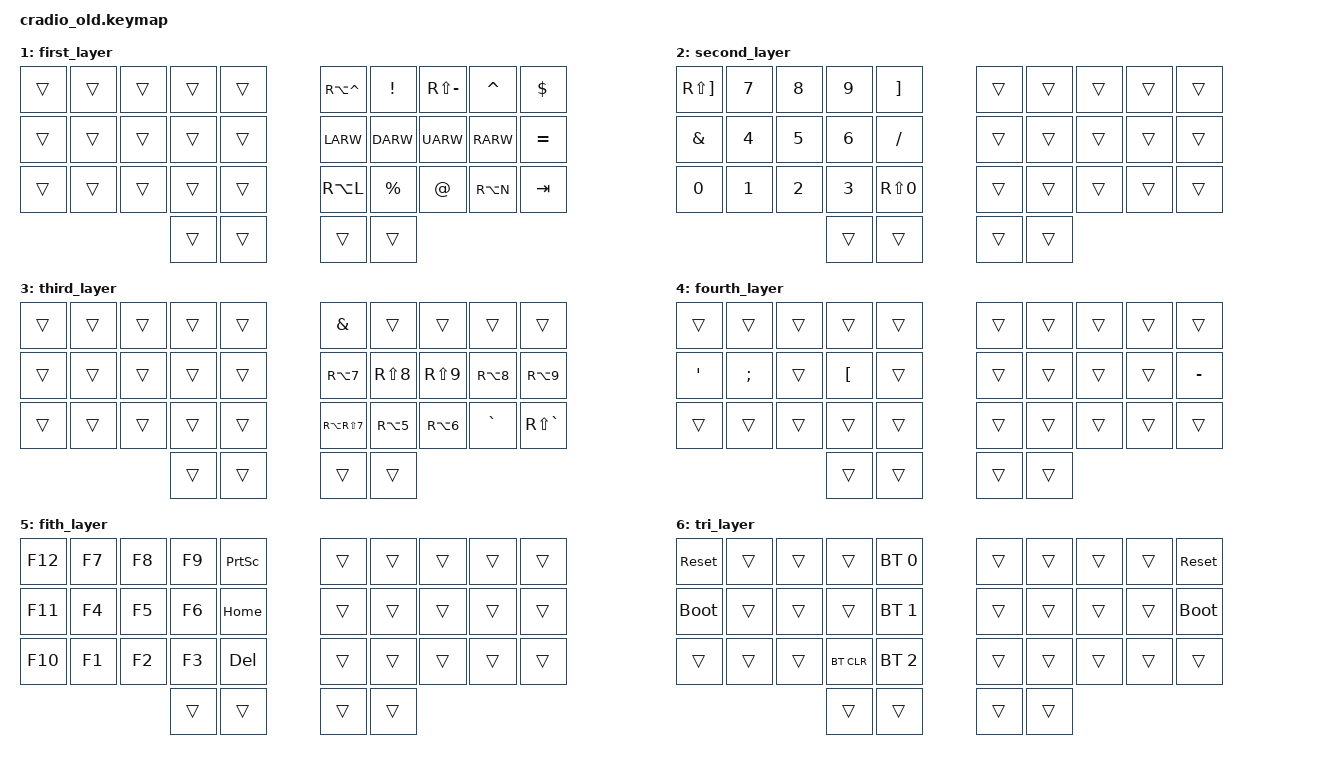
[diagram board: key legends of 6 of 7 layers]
// Copyright (c) 2022 The ZMK Contributors
// SPDX-License-Identifier: MIT

#include <behaviors.dtsi>
#include <dt-bindings/zmk/keys.h>
#include <dt-bindings/zmk/bt.h>

// Home row mods macro
#define HRML(k1,k2,k3,k4) &ht LCTRL k1  &ht LALT k2  &ht LGUI k3  &ht LSHFT k4
#define HRMR(k1,k2,k3,k4) &ht RSHFT k1  &ht RGUI k2  &ht RALT k3  &ht RCTRL k4

#define DEFAULT 0
#define QWERTZ 1
#define NAV 2
#define NUMS 3
#define SIGNS 4
#define DE 5
#define FUNC 6
#define SYSTEM 7


&lt {
    flavor = "tap-preferred";
    tapping-term-ms = <200>;
    quick-tap-ms = <200>;
};

/ {
    behaviors {
        ht: hold_tap {
            compatible = "zmk,behavior-hold-tap";
            #binding-cells = <2>;
            flavor = "tap-preferred";
            tapping-term-ms = <200>;
            quick-tap-ms = <200>;
            require-prior-idle-ms = <100>;
            bindings = <&kp>, <&kp>;
        };
    };

    conditional_layers {
        compatible = "zmk,conditional-layers";
        tri_layer {
            if-layers = <NAV NUMS>;
            then-layer = <SYSTEM>;
        };
    };

    keymap {
        compatible = "zmk,keymap";
        default_layer {
                        bindings = <
        //╭──────────┬──────────┬──────────┬──────────┬──────────╮   ╭──────────┬──────────┬──────────┬──────────┬──────────╮
        //│  Q       │  W       │  E       │  R       │  T       │   │  Y       │  U       │  I       │  O       │ - _      │
            &kp Q      &kp W      &kp E      &kp R      &kp T          &kp Y      &kp U      &kp I      &kp O      &kp FSLH
        //├──────────┼──────────┼──────────┼──────────┼──────────┤   ├──────────┼──────────┼──────────┼──────────┼──────────┤
        //│  A       │  S       │  D       │  F       │  G       │   │  H       │  J       │  K       │  L       │ P        │
            HRML(A,        S,         D,         F)     &kp G          &kp H      HRMR(J,        K,         L,        P)
        //├──────────┼──────────┼──────────┼──────────┼──────────┤   ├──────────┼──────────┼──────────┼──────────┼──────────┤
        //│  Z       │  X       │  C       │  V       │  B       │   │  N       │  M       │ , <      │ . >      │ # '      │
            &kp Z      &kp X      &kp C      &kp V      &kp B          &kp N      &kp M      &kp COMMA  &kp DOT    &lt FUNC BSLH
        //╰──────────┴──────────┴──────────┼──────────┼──────────┤   ├──────────┼──────────┼──────────┴──────────┴──────────╯
                                            &lt SIGNS ESC   &lt NAV BSPC   &lt NUMS SPACE &lt DE ENTER
        //                                 ╰──────────┴──────────╯   ╰──────────┴──────────╯
            >;
        };



        first_layer {
            bindings = <
        //╭──────────┬──────────┬──────────┬──────────┬──────────╮   ╭──────────┬──────────┬──────────┬──────────┬──────────╮
        //│          │          │          │          │          │   │ ^        │ !        │ ?        │ &        │  $       │
            &trans     &trans     &trans     &trans     &trans        &kp RA(CARET) &kp EXCL &kp RS(MINUS) &kp CARET &kp DLLR
        //├──────────┼──────────┼──────────┼──────────┼──────────┤   ├──────────┼──────────┼──────────┼──────────┼──────────┤
        //│          │          │          │          │          │   │ LEFT     │ DOWN     │ UP       │ RIGHT    │  ;       │
            &trans     &trans     &trans     &trans     &trans         &kp LARW   &kp DARW   &kp UARW   &kp RARW   &kp EQUAL
        //├──────────┼──────────┼──────────┼──────────┼──────────┤   ├──────────┼──────────┼──────────┼──────────┼──────────┤
        //│          │          │          │          │          │   │ @        │ %        │ "        │ ~        │          │
            &trans     &trans     &trans     &trans     &trans         &kp RA(L)  &kp PRCNT  &kp AT     &kp RA(N)  &kp TAB
        //╰──────────┴──────────┴──────────┼──────────┼──────────┤   ├──────────┼──────────┼──────────┴──────────┴──────────╯
                                             &trans     &trans            &trans     &trans
        //                                 ╰──────────┴──────────╯   ╰──────────┴──────────╯
            >;
        };

        second_layer {
            bindings = <
        //╭──────────┬──────────┬──────────┬──────────┬──────────╮   ╭──────────┬──────────┬──────────┬──────────┬──────────╮
        //│  *       │  7       │  8       │  9       │  +       │   │          │          │          │          │          │
           &kp RS(RBKT) &kp N7    &kp N8     &kp N9     &kp RBKT      &trans     &trans     &trans     &trans     &trans 
        //├──────────┼──────────┼──────────┼──────────┼──────────┤   ├──────────┼──────────┼──────────┼──────────┼──────────┤
        //│  7       │  4       │  5       │  6       │  -       │   │          │          │          │          │          │
            &kp AMPS   &kp N4     &kp N5     &kp N6     &kp FSLH        &trans     &trans     &trans     &trans     &trans 
        //├──────────┼──────────┼──────────┼──────────┼──────────┤   ├──────────┼──────────┼──────────┼──────────┼──────────┤
        //│  0       │  1       │  2       │  3       │  =       │   │          │          │          │          │          │
            &kp N0     &kp N1     &kp N2     &kp N3     &kp RS(N0)      &trans     &trans     &trans     &trans     &trans
        //╰──────────┴──────────┴──────────┼──────────┼──────────┤   ├──────────┼──────────┼──────────┴──────────┴──────────╯
                                             &trans     &trans         &trans     &trans
        //                                 ╰──────────┴──────────╯   ╰──────────┴──────────╯
            >;
        };

        third_layer {
            bindings = <
        //╭──────────┬──────────┬──────────┬──────────┬──────────╮   ╭──────────┬──────────┬──────────┬──────────┬──────────╮
        //│          │          │          │          │          │   │  /       │          │          │          │          │
            &trans     &trans     &trans     &trans     &trans         &kp AMPS   &trans     &trans     &trans     &trans 
        //├──────────┼──────────┼──────────┼──────────┼──────────┤   ├──────────┼──────────┼──────────┼──────────┼──────────┤
        //│          │          │          │          │          │   │  |       │  (       │  )       │  {       │  }       │
            &trans     &trans     &trans     &trans     &trans         &kp RA(N7) &kp RS(N8) &kp RS(N9) &kp RA(N8) &kp RA(N9) 
        //├──────────┼──────────┼──────────┼──────────┼──────────┤   ├──────────┼──────────┼──────────┼──────────┼──────────┤
        //│          │          │          │          │          │   │  \       │  [       │  ]       │  <       │  >       │
            &trans     &trans     &trans     &trans     &trans       &kp RA(RS(N7)) &kp RA(N5) &kp RA(N6) &kp GRAVE  &kp RS(GRAVE)
        //╰──────────┴──────────┴──────────┼──────────┼──────────┤   ├──────────┼──────────┼──────────┴──────────┴──────────╯
                                             &trans     &trans         &trans     &trans
        //                                 ╰──────────┴──────────╯   ╰──────────┴──────────╯
            >;
        };

        fourth_layer {
            bindings = <
        //╭──────────┬──────────┬──────────┬──────────┬──────────╮   ╭──────────┬──────────┬──────────┬──────────┬──────────╮
        //│          │          │          │          │          │   │          │          │          │          │          │
           &trans      &trans     &trans     &trans     &trans         &trans     &trans     &trans     &trans     &trans 
        //├──────────┼──────────┼──────────┼──────────┼──────────┤   ├──────────┼──────────┼──────────┼──────────┼──────────┤
        //│  ä       │  ö       │          │ ü        │          │   │          │          │          │          │  ß       │
            &kp SQT    &kp SEMI  &trans     &kp LBKT    &trans         &trans     &trans     &trans     &trans     &kp MINUS 
        //├──────────┼──────────┼──────────┼──────────┼──────────┤   ├──────────┼──────────┼──────────┼──────────┼──────────┤
        //│          │          │          │          │          │   │          │          │          │          │          │
            &trans     &trans     &trans     &trans     &trans         &trans     &trans     &trans     &trans     &trans
        //╰──────────┴──────────┴──────────┼──────────┼──────────┤   ├──────────┼──────────┼──────────┴──────────┴──────────╯
                                             &trans     &trans         &trans     &trans
        //                                 ╰──────────┴──────────╯   ╰──────────┴──────────╯
            >;
        };

        fith_layer {
            bindings = <
        //╭──────────┬──────────┬──────────┬──────────┬──────────╮   ╭──────────┬──────────┬──────────┬──────────┬──────────╮
        //│          │          │          │          │          │   │          │          │          │          │          │
            &kp F12     &kp F7     &kp F8     &kp F9    &kp PSCRN          &trans     &trans     &trans     &trans    &trans
        //├──────────┼──────────┼──────────┼──────────┼──────────┤   ├──────────┼──────────┼──────────┼──────────┼──────────┤
        //│          │          │          │          │          │   │          │          │          │          │
            &kp F11     &kp F4     &kp F5     &kp F6    &kp HOME          &trans     &trans     &trans     &trans     &trans
        //├──────────┼──────────┼──────────┼──────────┼──────────┤   ├──────────┼──────────┼──────────┼──────────┼──────────┤
        //│          │          │          │          │          │   │          │          │          │          │          │
            &kp F10     &kp F1     &kp F2     &kp F3    &kp DEL          &trans     &trans     &trans     &trans     &trans
        //╰──────────┴──────────┴──────────┼──────────┼──────────┤   ├──────────┼──────────┼──────────┴──────────┴──────────╯
                                             &trans     &trans         &trans     &trans
        //                                 ╰──────────┴──────────╯   ╰──────────┴──────────╯
            >;
        };

        tri_layer {
            bindings = <
        //╭──────────┬──────────┬──────────┬──────────┬──────────╮   ╭──────────┬──────────┬──────────┬──────────┬──────────╮
        //│ RESET    │          │          │          │PROFILE 0 │   │          │          │          │          │  RESET   │
           &sys_reset  &trans     &trans     &trans    &bt BT_SEL 0    &trans     &trans     &trans     &trans    &sys_reset
        //├──────────┼──────────┼──────────┼──────────┼──────────┤   ├──────────┼──────────┼──────────┼──────────┼──────────┤
        //│BOOTLOADER│          │          │          │PROFILE 1 │   │          │          │          │          │BOOTLOADER│
          &bootloader  &trans     &trans     &trans   &bt BT_SEL 1    &trans     &trans     &trans     &trans    &bootloader
        //├──────────┼──────────┼──────────┼──────────┼──────────┤   ├──────────┼──────────┼──────────┼──────────┼──────────┤
        //│          │          │          │ CLEAR BT │PROFILE 2 │   │          │          │          │          │          │
            &trans     &trans     &trans    &bt BT_CLR &bt BT_SEL 2    &trans     &trans     &trans     &trans     &trans
        //╰──────────┴──────────┴──────────┼──────────┼──────────┤   ├──────────┼──────────┼──────────┴──────────┴──────────╯
                                             &trans     &trans         &trans     &trans
        //                                 ╰──────────┴──────────╯   ╰──────────┴──────────╯
            >;
        };

    };
};
